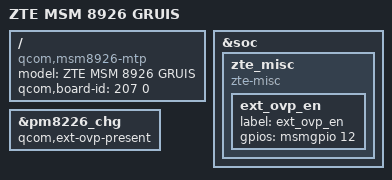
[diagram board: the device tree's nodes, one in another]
/* Copyright (c) 2013, The Linux Foundation. All rights reserved.
 *
 * This program is free software; you can redistribute it and/or modify
 * it under the terms of the GNU General Public License version 2 and
 * only version 2 as published by the Free Software Foundation.
 *
 * This program is distributed in the hope that it will be useful,
 * but WITHOUT ANY WARRANTY; without even the implied warranty of
 * MERCHANTABILITY or FITNESS FOR A PARTICULAR PURPOSE.  See the
 * GNU General Public License for more details.
 */


/dts-v1/;
/include/ "msm8926.dtsi"
/include/ "msm8226-720p-mtp.dtsi"
/include/ "msm8226-camera-sensor-mtp.dtsi"
/include/ "msm8926-zte-gruis.dtsi"
/include/ "dsi-panel-orise9608a-boe-4p5-qhd-video-zte-400.dtsi"
/include/ "dsi-panel-nt35516-tm-4p5-qhd-video-zte-401.dtsi"
/include/ "dsi-panel-zte-tm-otm8018-wvga-video.dtsi"
/include/ "dsi-panel-zte-hsd-nt35512-wvga-video.dtsi"

/ {
	model = "ZTE MSM 8926 GRUIS";
	compatible = "qcom,msm8926-mtp", "qcom,msm8926", "qcom,mtp";
	qcom,board-id = <207 0>;
};
&soc {
	zte_misc {
		compatible = "zte-misc";
		ext_ovp_en {
			label = "ext_ovp_en";
			gpios = <&msmgpio 12 0x0>;
		};
	};

};
&pm8226_chg {
	qcom,ext-ovp-present;
};
